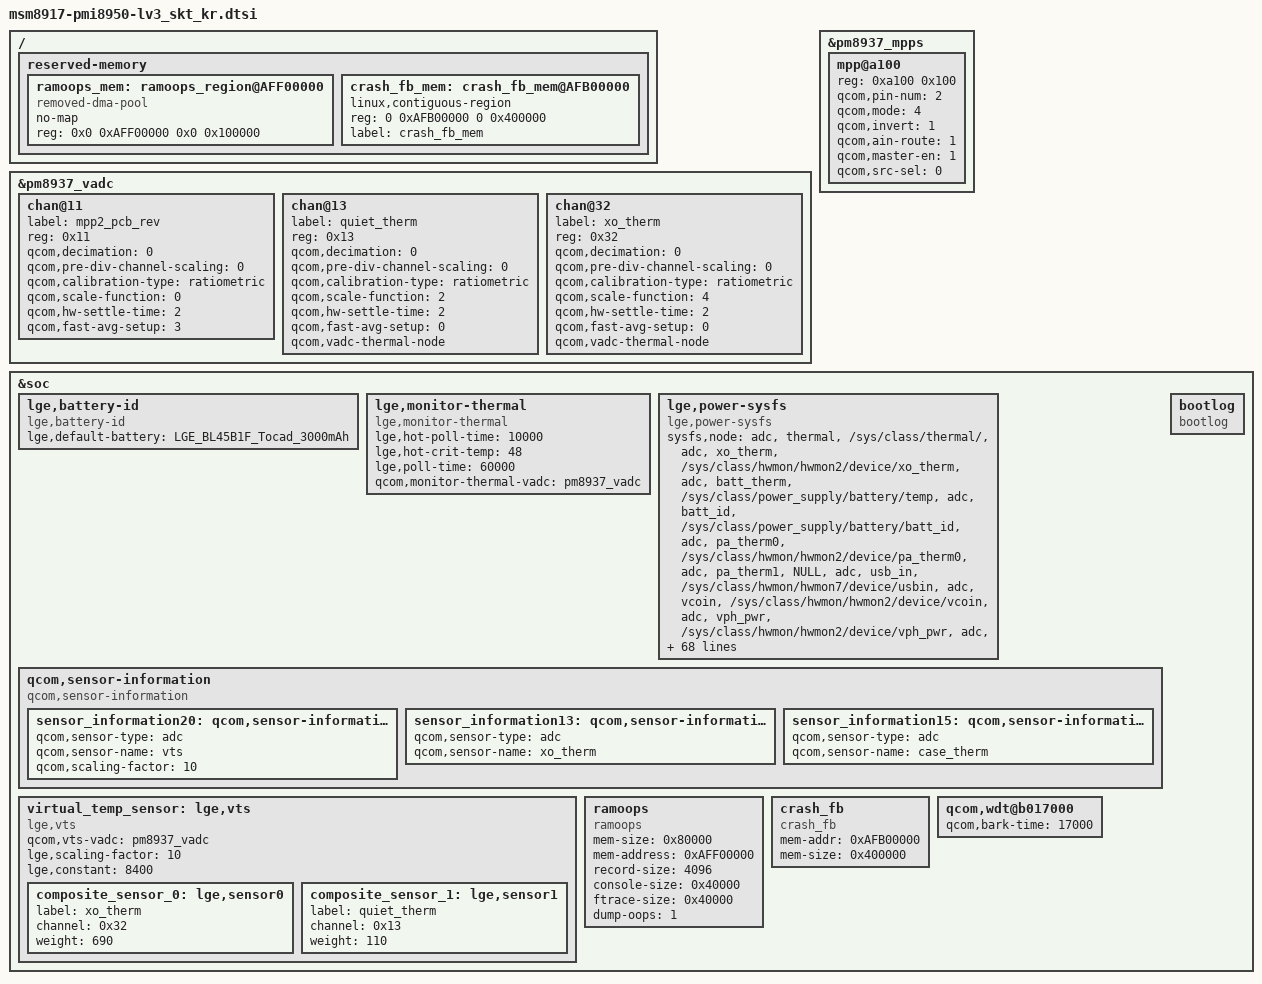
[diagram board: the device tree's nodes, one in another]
/*
 * Copyright (c) 2016, The Linux Foundation. All rights reserved.
 *
 * This program is free software; you can redistribute it and/or modify
 * it under the terms of the GNU General Public License version 2 and
 * only version 2 as published by the Free Software Foundation.
 *
 * This program is distributed in the hope that it will be useful,
 * but WITHOUT ANY WARRANTY; without even the implied warranty of
 * MERCHANTABILITY or FITNESS FOR A PARTICULAR PURPOSE.  See the
 * GNU General Public License for more details.
 */

&pm8937_vadc {
	chan@11 {
		label = "mpp2_pcb_rev";
		reg = <0x11>;
		qcom,decimation = <0>;
		qcom,pre-div-channel-scaling = <0>;
		qcom,calibration-type = "ratiometric";
		qcom,scale-function = <0>;
		qcom,hw-settle-time = <2>;
		qcom,fast-avg-setup = <3>;
	};

	chan@13 {
		label = "quiet_therm";
		reg = <0x13>;
		qcom,decimation = <0>;
		qcom,pre-div-channel-scaling = <0>;
		qcom,calibration-type = "ratiometric";
		qcom,scale-function = <2>;
		qcom,hw-settle-time = <2>;
		qcom,fast-avg-setup = <0>;
		qcom,vadc-thermal-node;
	};

	chan@32 {
		label = "xo_therm";
		reg = <0x32>;
		qcom,decimation = <0>;
		qcom,pre-div-channel-scaling = <0>;
		qcom,calibration-type = "ratiometric";
		qcom,scale-function = <4>;
		qcom,hw-settle-time = <2>;
		qcom,fast-avg-setup = <0>;
		qcom,vadc-thermal-node;
	};
};

&pm8937_mpps {
	mpp@a100 {
		reg = <0xa100 0x100>;
		qcom,pin-num = <2>;
		qcom,mode = <4>; /* AIN input */
		qcom,invert = <1>; /* Enable MPP */
		qcom,ain-route = <1>; /* AMUX 6 */
		qcom,master-en = <1>;
		qcom,src-sel = <0>; /* Function constant */
	};
};

&soc {
	lge,battery-id{
		compatible = "lge,battery-id";
		/* lge,restrict-mode-enabled; */
		lge,default-battery = "LGE_BL45B1F_Tocad_3000mAh";
	};

	lge,monitor-thermal {
		compatible = "lge,monitor-thermal";
		status = "ok";
		lge,hot-poll-time = <10000>;
		lge,hot-crit-temp = <48>;
		lge,poll-time = <60000>;
		qcom,monitor-thermal-vadc = <&pm8937_vadc>;
	};

	lge,power-sysfs {
		compatible = "lge,power-sysfs";

		sysfs,node =
			/* group , user_node,  kernel node */
			/* ADC/MPP */
			"adc", "thermal", "/sys/class/thermal/",
			"adc", "xo_therm", "/sys/class/hwmon/hwmon2/device/xo_therm",
			"adc", "batt_therm", "/sys/class/power_supply/battery/temp",
			"adc", "batt_id", "/sys/class/power_supply/battery/batt_id",
			"adc", "pa_therm0", "/sys/class/hwmon/hwmon2/device/pa_therm0",
			"adc", "pa_therm1", "NULL", /* Not use */
			"adc", "usb_in", "/sys/class/hwmon/hwmon7/device/usbin",
			"adc", "vcoin", "/sys/class/hwmon/hwmon2/device/vcoin",
			"adc", "vph_pwr", "/sys/class/hwmon/hwmon2/device/vph_pwr",
			"adc", "usb_id", "/sys/class/hwmon/hwmon7/device/mpp1_usb_id",
			"adc", "quiet_therm", "/sys/class/hwmon/hwmon2/device/quiet_therm",
			/* Battery */
			"battery", "capacity", "/sys/class/power_supply/battery/capacity",
			"battery", "health", "/sys/class/power_supply/battery/health",
			"battery", "present", "/sys/class/power_supply/battery/present",
			"battery", "pseudo_batt", "/sys/class/power_supply/battery/pseudo_batt",
			"battery", "status", "/sys/class/power_supply/battery/status",
			"battery", "temp", "/sys/class/power_supply/battery/temp",
			"battery", "valid_batt_id", "/sys/class/power_supply/battery/valid_batt_id",
			"battery", "voltage_now", "/sys/class/power_supply/battery/voltage_now",
			/* Charger */
			"charger", "ac_online", "NULL",
			"charger", "usb_online", "/sys/class/power_supply/usb/online",
			"charger", "present", "/sys/class/power_supply/usb/present",
			"charger", "wlc_online", "NULL",
			"charger", "type", "/sys/class/power_supply/usb/type",
			"charger", "time_out", "/sys/class/power_supply/battery/safety_timer_enabled",
			"charger", "charging_enabled", "/sys/class/power_supply/battery/charging_enabled",
			"charger", "ibat_current", "/sys/class/power_supply/battery/current_now",
			"charger", "ichg_current", "/sys/class/power_supply/usb/current_max",
			"charger", "iusb_control", "NULL",
			"charger", "thermal_mitigation", "/sys/module/qpnp_linear_charger/parameters/qpnp_thermal_mitigation", /* Fix */
			"charger", "wlc_thermal_mitigation", "NULL",
			"charger", "usb_parallel_chg_status", "NULL",
			"charger", "usb_parallel_charging_enabled", "NULL",
			"charger", "quick_charging_state", "/sys/module/qpnp_smbcharger/parameters/quick_charging_state",
			/* LCD Backlight */
			"lcd", "brightness", "/sys/class/leds/lcd-backlight/brightness",
			"lcd", "max_brightness", "/sys/class/leds/lcd-backlight/max_brightness",
			/* KEY LED */
			"key_led", "red_brightness", "NULL",
			"key_led", "green_brightness", "NULL",
			"key_led", "blue_brightness", "NULL",
			/* CPU */
			"cpu", "cpu_idle_modes", "NULL",
			/* GPU */
			"gpu", "busy", "/sys/class/kgsl/kgsl-3d0/gpubusy",
			/* PLATFORM */
			"platform", "speed_bin", "NULL",
			"platform", "pvs_bin", "NULL",
			"platform", "power_state", "/sys/power/autosleep",
			"platform", "poweron_alarm", "/sys/module/qpnp_rtc/parameters/poweron_alarm",
			"platform", "pcb_rev", "/sys/class/power_supply/battery/hw_rev",
			/* testmode */
			"testmode", "charge", "/sys/class/power_supply/battery/device/at_charge",
			"testmode", "chcomp", "/sys/class/power_supply/battery/device/at_chcomp",
			"testmode", "chgmodeoff", "/sys/class/power_supply/battery/charging_enabled",
			"testmode", "fuelrst", "NULL",
			"testmode", "rtc_time", "/dev/rtc0",
			"testmode", "pmrst", "NULL",
			"testmode", "battexit", "/sys/class/power_supply/battery/present"
			;
	};

	qcom,sensor-information {
		compatible = "qcom,sensor-information";

		sensor_information20: qcom,sensor-information-12 {
			qcom,sensor-type = "adc";
			qcom,sensor-name = "vts";
			qcom,scaling-factor = <10>;
		};

		sensor_information13: qcom,sensor-information-13 {
			qcom,sensor-type = "adc";
			qcom,sensor-name = "xo_therm";
		};

		sensor_information15: qcom,sensor-information-15 {
			qcom,sensor-type = "adc";
			qcom,sensor-name = "case_therm";
		};
	};

	/* vst = (0.42*xo_therm) + (0.44*quiet_therm) + 4.6 */
	virtual_temp_sensor: lge,vts {
		compatible = "lge,vts";
		qcom,vts-vadc = <&pm8937_vadc>;
		lge,scaling-factor= <10>;
		lge,constant = <8400>;
		composite_sensor_0: lge,sensor0 {
			label = "xo_therm";
			channel = <0x32>;
			weight = <690>;
		};
		composite_sensor_1: lge,sensor1 {
			label = "quiet_therm";
			channel = <0x13>;
			weight = <110>;
		};
	};
};

/ {
	reserved-memory {
		ramoops_mem: ramoops_region@AFF00000 {
			compatible = "removed-dma-pool";
			no-map;
			reg = <0x0 0xAFF00000 0x0 0x100000>;
		};

		crash_fb_mem: crash_fb_mem@AFB00000 {
			linux,contiguous-region;
			reg = <0 0xAFB00000 0 0x400000>;
			label = "crash_fb_mem";
		};
	};
};

&soc {
	ramoops {
		compatible = "ramoops";
		mem-size = <0x80000>;
		mem-address = <0xAFF00000>;
		record-size = <4096>;
		console-size = <0x40000>;
		ftrace-size = <0x40000>;
		dump-oops = <1>;
	};

	bootlog {
		compatible = "bootlog";
	};

	crash_fb {
		compatible = "crash_fb";
		mem-addr = <0xAFB00000>;
		mem-size = <0x400000>;
	};

	qcom,wdt@b017000 {
		qcom,bark-time = <17000>;
        };
};

#include "msm8917-lv3_skt_kr-pinctrl.dtsi"
#include "msm8917-pmi8950-lv3_skt_kr-camera.dtsi"
#include "msm8917-lv3_skt_kr-panel.dtsi"
#include "msm8917-lv3_skt_kr-sound.dtsi"
#include "msm8917-lv3_skt_kr-misc.dtsi"
#include "msm8917-pmi8950-lv3_skt_kr-pm.dtsi"
#include "msm8917-lv3_skt_kr-touch.dtsi"
#include "msm8917-pmi8950-lv3_skt_kr-usb.dtsi"
